# AST1080 register map
File version: 1.0
CPU: CM4 r0p1, little endian, MPU, FPU, 4 interrupt priority bits, 256 interrupts
Registers are 32-bit, read-write, reset 0x0 unless marked. A register's access mark holds for its fields unless they carry their own. Offsets are from the block's base; [hi:lo] are bit positions; {n}, {i} and the like mark numbered series; 'fields as' and 'values as' point back to an identical list.

## gpio (part 2 of 2)
Base 0x74C0B000
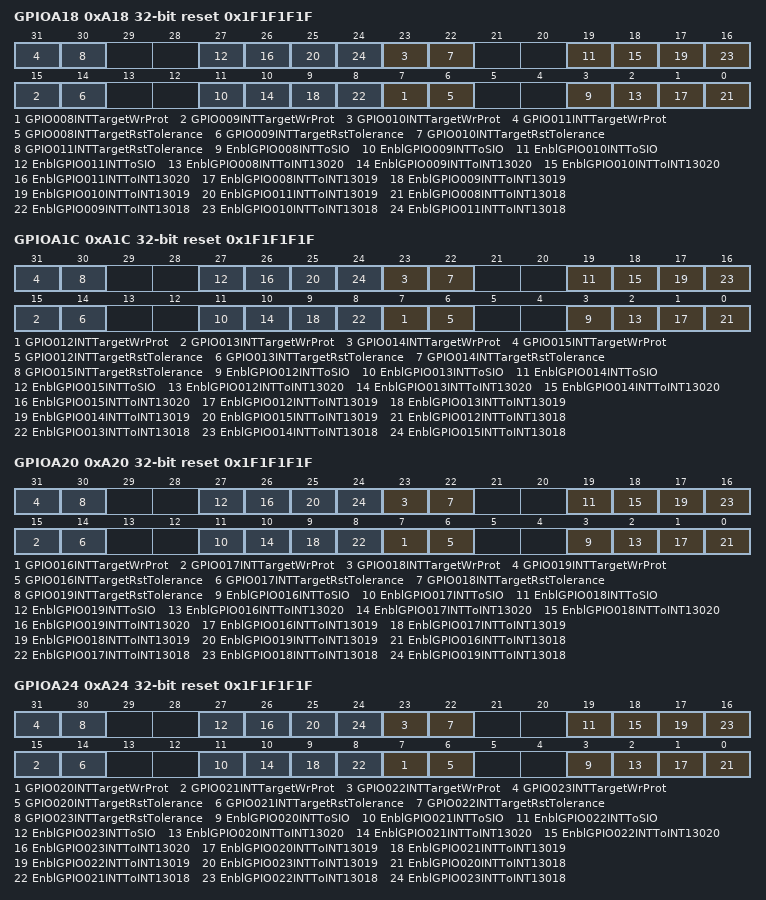
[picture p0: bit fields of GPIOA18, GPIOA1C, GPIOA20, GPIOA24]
0xA18 GPIOA18 reset 0x1F1F1F1F — GPIO Interrupt Target Control Register \#2
  [8n-57] GPIO{n:03}INTTargetWrProt (n=8..11) — GPIO{n:03} Interrupt Target Write Protection
  [8n-58] GPIO{n:03}INTTargetRstTolerance (n=8..11) — GPIO{n:03} Interrupt Target Reset Tolerance
    0=Interrupt_Target_Is_Reset_By_WDT; 1=Interrupt_Target_Is_NOT_Reset_By_WDT
  [8n-61] EnblGPIO{n:03}INTToSIO (n=8..11) — Enable GPIO{n:03} Interrupt To SIO
  [8n-62] EnblGPIO{n:03}INTToINT13020 (n=8..11) — Enable GPIO{n:03} Interrupt To INT#130_20
  [8n-63] EnblGPIO{n:03}INTToINT13019 (n=8..11) — Enable GPIO{n:03} Interrupt To INT#130_19
  [8n-64] EnblGPIO{n:03}INTToINT13018 (n=8..11) — Enable GPIO{n:03} Interrupt To INT#130_18
0xA1C GPIOA1C reset 0x1F1F1F1F — GPIO Interrupt Target Control Register \#3
  [8n-89] GPIO{n:03}INTTargetWrProt (n=12..15) — GPIO{n:03} Interrupt Target Write Protection
  [8n-90] GPIO{n:03}INTTargetRstTolerance (n=12..15) — GPIO{n:03} Interrupt Target Reset Tolerance
    values as GPIOA18.GPIO008INTTargetRstTolerance
  [8n-93] EnblGPIO{n:03}INTToSIO (n=12..15) — Enable GPIO{n:03} Interrupt To SIO
  [8n-94] EnblGPIO{n:03}INTToINT13020 (n=12..15) — Enable GPIO{n:03} Interrupt To INT#130_20
  [8n-95] EnblGPIO{n:03}INTToINT13019 (n=12..15) — Enable GPIO{n:03} Interrupt To INT#130_19
  [8n-96] EnblGPIO{n:03}INTToINT13018 (n=12..15) — Enable GPIO{n:03} Interrupt To INT#130_18
0xA20 GPIOA20 reset 0x1F1F1F1F — GPIO Interrupt Target Control Register \#4
  [8n-121] GPIO{n:03}INTTargetWrProt (n=16..19) — GPIO{n:03} Interrupt Target Write Protection
  [8n-122] GPIO{n:03}INTTargetRstTolerance (n=16..19) — GPIO{n:03} Interrupt Target Reset Tolerance
    values as GPIOA18.GPIO008INTTargetRstTolerance
  [8n-125] EnblGPIO{n:03}INTToSIO (n=16..19) — Enable GPIO{n:03} Interrupt To SIO
  [8n-126] EnblGPIO{n:03}INTToINT13020 (n=16..19) — Enable GPIO{n:03} Interrupt To INT#130_20
  [8n-127] EnblGPIO{n:03}INTToINT13019 (n=16..19) — Enable GPIO{n:03} Interrupt To INT#130_19
  [8n-128] EnblGPIO{n:03}INTToINT13018 (n=16..19) — Enable GPIO{n:03} Interrupt To INT#130_18
0xA24 GPIOA24 reset 0x1F1F1F1F — GPIO Interrupt Target Control Register \#5
  [8n-153] GPIO{n:03}INTTargetWrProt (n=20..23) — GPIO{n:03} Interrupt Target Write Protection
  [8n-154] GPIO{n:03}INTTargetRstTolerance (n=20..23) — GPIO{n:03} Interrupt Target Reset Tolerance
    values as GPIOA18.GPIO008INTTargetRstTolerance
  [8n-157] EnblGPIO{n:03}INTToSIO (n=20..23) — Enable GPIO{n:03} Interrupt To SIO
  [8n-158] EnblGPIO{n:03}INTToINT13020 (n=20..23) — Enable GPIO{n:03} Interrupt To INT#130_20
  [8n-159] EnblGPIO{n:03}INTToINT13019 (n=20..23) — Enable GPIO{n:03} Interrupt To INT#130_19
  [8n-160] EnblGPIO{n:03}INTToINT13018 (n=20..23) — Enable GPIO{n:03} Interrupt To INT#130_18
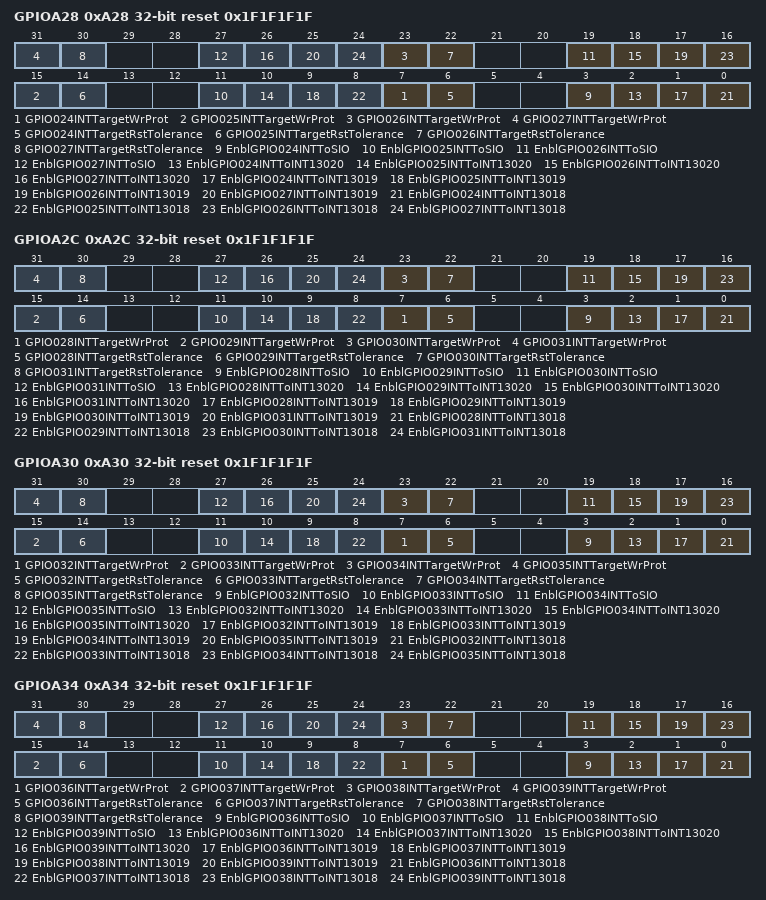
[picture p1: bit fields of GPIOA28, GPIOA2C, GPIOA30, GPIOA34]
0xA28 GPIOA28 reset 0x1F1F1F1F — GPIO Interrupt Target Control Register \#6
  [8n-185] GPIO{n:03}INTTargetWrProt (n=24..27) — GPIO{n:03} Interrupt Target Write Protection
  [8n-186] GPIO{n:03}INTTargetRstTolerance (n=24..27) — GPIO{n:03} Interrupt Target Reset Tolerance
    values as GPIOA18.GPIO008INTTargetRstTolerance
  [8n-189] EnblGPIO{n:03}INTToSIO (n=24..27) — Enable GPIO{n:03} Interrupt To SIO
  [8n-190] EnblGPIO{n:03}INTToINT13020 (n=24..27) — Enable GPIO{n:03} Interrupt To INT#130_20
  [8n-191] EnblGPIO{n:03}INTToINT13019 (n=24..27) — Enable GPIO{n:03} Interrupt To INT#130_19
  [8n-192] EnblGPIO{n:03}INTToINT13018 (n=24..27) — Enable GPIO{n:03} Interrupt To INT#130_18
0xA2C GPIOA2C reset 0x1F1F1F1F — GPIO Interrupt Target Control Register \#7
  [8n-217] GPIO{n:03}INTTargetWrProt (n=28..31) — GPIO{n:03} Interrupt Target Write Protection
  [8n-218] GPIO{n:03}INTTargetRstTolerance (n=28..31) — GPIO{n:03} Interrupt Target Reset Tolerance
    values as GPIOA18.GPIO008INTTargetRstTolerance
  [8n-221] EnblGPIO{n:03}INTToSIO (n=28..31) — Enable GPIO{n:03} Interrupt To SIO
  [8n-222] EnblGPIO{n:03}INTToINT13020 (n=28..31) — Enable GPIO{n:03} Interrupt To INT#130_20
  [8n-223] EnblGPIO{n:03}INTToINT13019 (n=28..31) — Enable GPIO{n:03} Interrupt To INT#130_19
  [8n-224] EnblGPIO{n:03}INTToINT13018 (n=28..31) — Enable GPIO{n:03} Interrupt To INT#130_18
0xA30 GPIOA30 reset 0x1F1F1F1F — GPIO Interrupt Target Control Register \#8
  [8n-249] GPIO{n:03}INTTargetWrProt (n=32..35) — GPIO{n:03} Interrupt Target Write Protection
  [8n-250] GPIO{n:03}INTTargetRstTolerance (n=32..35) — GPIO{n:03} Interrupt Target Reset Tolerance
    values as GPIOA18.GPIO008INTTargetRstTolerance
  [8n-253] EnblGPIO{n:03}INTToSIO (n=32..35) — Enable GPIO{n:03} Interrupt To SIO
  [8n-254] EnblGPIO{n:03}INTToINT13020 (n=32..35) — Enable GPIO{n:03} Interrupt To INT#130_20
  [8n-255] EnblGPIO{n:03}INTToINT13019 (n=32..35) — Enable GPIO{n:03} Interrupt To INT#130_19
  [8n-256] EnblGPIO{n:03}INTToINT13018 (n=32..35) — Enable GPIO{n:03} Interrupt To INT#130_18
0xA34 GPIOA34 reset 0x1F1F1F1F — GPIO Interrupt Target Control Register \#9
  [8n-281] GPIO{n:03}INTTargetWrProt (n=36..39) — GPIO{n:03} Interrupt Target Write Protection
  [8n-282] GPIO{n:03}INTTargetRstTolerance (n=36..39) — GPIO{n:03} Interrupt Target Reset Tolerance
    values as GPIOA18.GPIO008INTTargetRstTolerance
  [8n-285] EnblGPIO{n:03}INTToSIO (n=36..39) — Enable GPIO{n:03} Interrupt To SIO
  [8n-286] EnblGPIO{n:03}INTToINT13020 (n=36..39) — Enable GPIO{n:03} Interrupt To INT#130_20
  [8n-287] EnblGPIO{n:03}INTToINT13019 (n=36..39) — Enable GPIO{n:03} Interrupt To INT#130_19
  [8n-288] EnblGPIO{n:03}INTToINT13018 (n=36..39) — Enable GPIO{n:03} Interrupt To INT#130_18
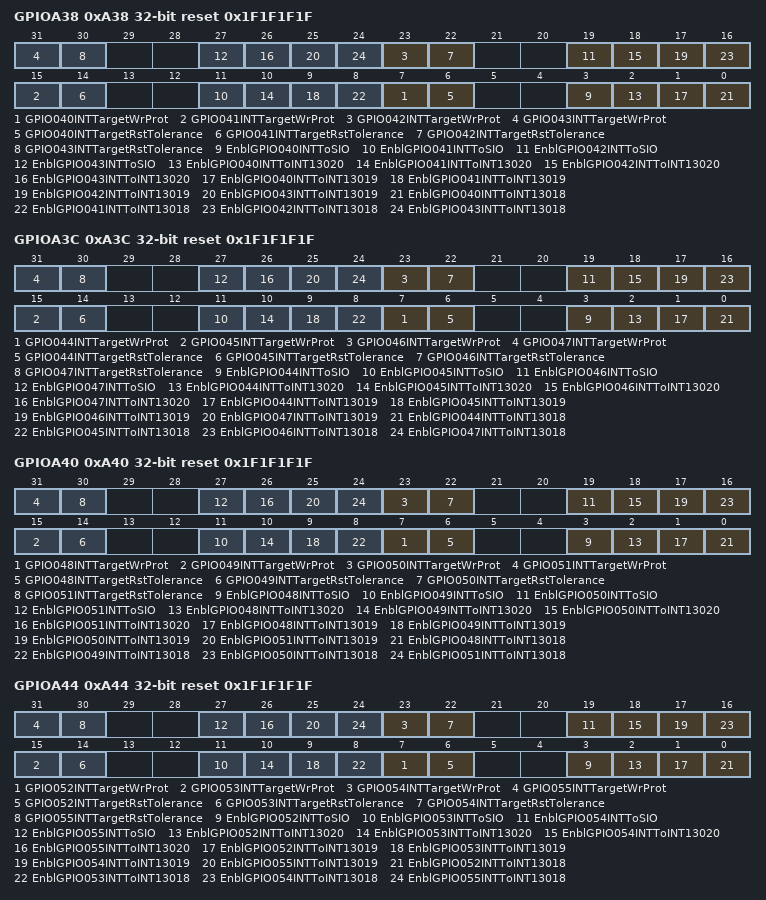
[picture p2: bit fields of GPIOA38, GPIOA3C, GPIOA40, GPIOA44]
0xA38 GPIOA38 reset 0x1F1F1F1F — GPIO Interrupt Target Control Register \#10
  [8n-313] GPIO{n:03}INTTargetWrProt (n=40..43) — GPIO{n:03} Interrupt Target Write Protection
  [8n-314] GPIO{n:03}INTTargetRstTolerance (n=40..43) — GPIO{n:03} Interrupt Target Reset Tolerance
    values as GPIOA18.GPIO008INTTargetRstTolerance
  [8n-317] EnblGPIO{n:03}INTToSIO (n=40..43) — Enable GPIO{n:03} Interrupt To SIO
  [8n-318] EnblGPIO{n:03}INTToINT13020 (n=40..43) — Enable GPIO{n:03} Interrupt To INT#130_20
  [8n-319] EnblGPIO{n:03}INTToINT13019 (n=40..43) — Enable GPIO{n:03} Interrupt To INT#130_19
  [8n-320] EnblGPIO{n:03}INTToINT13018 (n=40..43) — Enable GPIO{n:03} Interrupt To INT#130_18
0xA3C GPIOA3C reset 0x1F1F1F1F — GPIO Interrupt Target Control Register \#11
  [8n-345] GPIO{n:03}INTTargetWrProt (n=44..47) — GPIO{n:03} Interrupt Target Write Protection
  [8n-346] GPIO{n:03}INTTargetRstTolerance (n=44..47) — GPIO{n:03} Interrupt Target Reset Tolerance
    values as GPIOA18.GPIO008INTTargetRstTolerance
  [8n-349] EnblGPIO{n:03}INTToSIO (n=44..47) — Enable GPIO{n:03} Interrupt To SIO
  [8n-350] EnblGPIO{n:03}INTToINT13020 (n=44..47) — Enable GPIO{n:03} Interrupt To INT#130_20
  [8n-351] EnblGPIO{n:03}INTToINT13019 (n=44..47) — Enable GPIO{n:03} Interrupt To INT#130_19
  [8n-352] EnblGPIO{n:03}INTToINT13018 (n=44..47) — Enable GPIO{n:03} Interrupt To INT#130_18
0xA40 GPIOA40 reset 0x1F1F1F1F — GPIO Interrupt Target Control Register \#12
  [8n-377] GPIO{n:03}INTTargetWrProt (n=48..51) — GPIO{n:03} Interrupt Target Write Protection
  [8n-378] GPIO{n:03}INTTargetRstTolerance (n=48..51) — GPIO{n:03} Interrupt Target Reset Tolerance
    values as GPIOA18.GPIO008INTTargetRstTolerance
  [8n-381] EnblGPIO{n:03}INTToSIO (n=48..51) — Enable GPIO{n:03} Interrupt To SIO
  [8n-382] EnblGPIO{n:03}INTToINT13020 (n=48..51) — Enable GPIO{n:03} Interrupt To INT#130_20
  [8n-383] EnblGPIO{n:03}INTToINT13019 (n=48..51) — Enable GPIO{n:03} Interrupt To INT#130_19
  [8n-384] EnblGPIO{n:03}INTToINT13018 (n=48..51) — Enable GPIO{n:03} Interrupt To INT#130_18
0xA44 GPIOA44 reset 0x1F1F1F1F — GPIO Interrupt Target Control Register \#13
  [8n-409] GPIO{n:03}INTTargetWrProt (n=52..55) — GPIO{n:03} Interrupt Target Write Protection
  [8n-410] GPIO{n:03}INTTargetRstTolerance (n=52..55) — GPIO{n:03} Interrupt Target Reset Tolerance
    values as GPIOA18.GPIO008INTTargetRstTolerance
  [8n-413] EnblGPIO{n:03}INTToSIO (n=52..55) — Enable GPIO{n:03} Interrupt To SIO
  [8n-414] EnblGPIO{n:03}INTToINT13020 (n=52..55) — Enable GPIO{n:03} Interrupt To INT#130_20
  [8n-415] EnblGPIO{n:03}INTToINT13019 (n=52..55) — Enable GPIO{n:03} Interrupt To INT#130_19
  [8n-416] EnblGPIO{n:03}INTToINT13018 (n=52..55) — Enable GPIO{n:03} Interrupt To INT#130_18
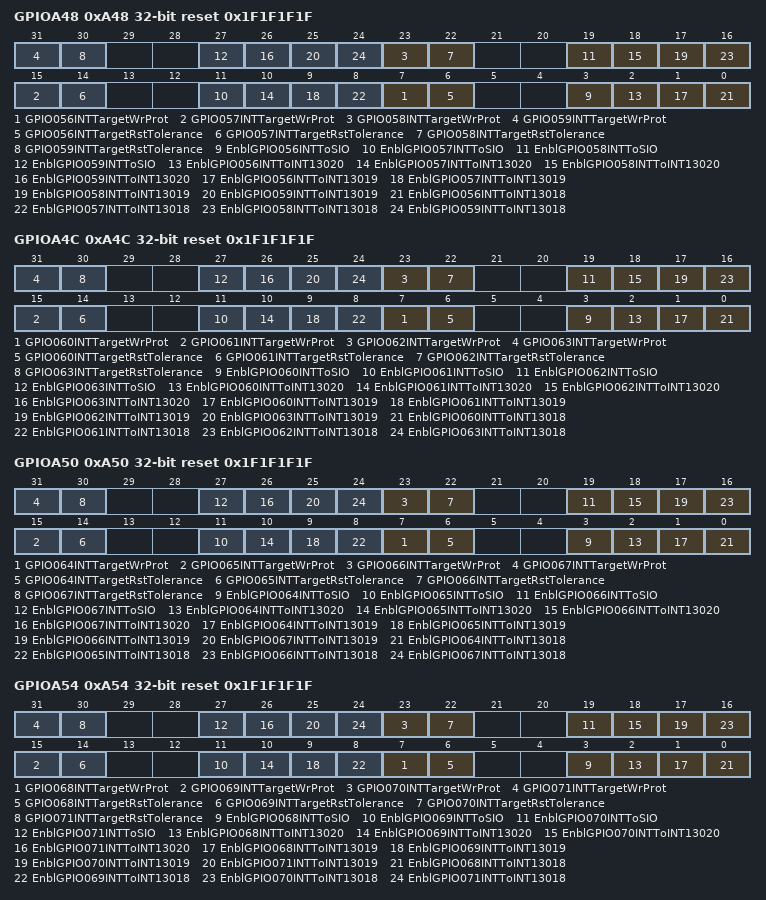
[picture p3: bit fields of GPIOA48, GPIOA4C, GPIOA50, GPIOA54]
0xA48 GPIOA48 reset 0x1F1F1F1F — GPIO Interrupt Target Control Register \#14
  [8n-441] GPIO{n:03}INTTargetWrProt (n=56..59) — GPIO{n:03} Interrupt Target Write Protection
  [8n-442] GPIO{n:03}INTTargetRstTolerance (n=56..59) — GPIO{n:03} Interrupt Target Reset Tolerance
    values as GPIOA18.GPIO008INTTargetRstTolerance
  [8n-445] EnblGPIO{n:03}INTToSIO (n=56..59) — Enable GPIO{n:03} Interrupt To SIO
  [8n-446] EnblGPIO{n:03}INTToINT13020 (n=56..59) — Enable GPIO{n:03} Interrupt To INT#130_20
  [8n-447] EnblGPIO{n:03}INTToINT13019 (n=56..59) — Enable GPIO{n:03} Interrupt To INT#130_19
  [8n-448] EnblGPIO{n:03}INTToINT13018 (n=56..59) — Enable GPIO{n:03} Interrupt To INT#130_18
0xA4C GPIOA4C reset 0x1F1F1F1F — GPIO Interrupt Target Control Register \#15
  [8n-473] GPIO{n:03}INTTargetWrProt (n=60..63) — GPIO{n:03} Interrupt Target Write Protection
  [8n-474] GPIO{n:03}INTTargetRstTolerance (n=60..63) — GPIO{n:03} Interrupt Target Reset Tolerance
    values as GPIOA18.GPIO008INTTargetRstTolerance
  [8n-477] EnblGPIO{n:03}INTToSIO (n=60..63) — Enable GPIO{n:03} Interrupt To SIO
  [8n-478] EnblGPIO{n:03}INTToINT13020 (n=60..63) — Enable GPIO{n:03} Interrupt To INT#130_20
  [8n-479] EnblGPIO{n:03}INTToINT13019 (n=60..63) — Enable GPIO{n:03} Interrupt To INT#130_19
  [8n-480] EnblGPIO{n:03}INTToINT13018 (n=60..63) — Enable GPIO{n:03} Interrupt To INT#130_18
0xA50 GPIOA50 reset 0x1F1F1F1F — GPIO Interrupt Target Control Register \#16
  [8n-505] GPIO{n:03}INTTargetWrProt (n=64..67) — GPIO{n:03} Interrupt Target Write Protection
  [8n-506] GPIO{n:03}INTTargetRstTolerance (n=64..67) — GPIO{n:03} Interrupt Target Reset Tolerance
    values as GPIOA18.GPIO008INTTargetRstTolerance
  [8n-509] EnblGPIO{n:03}INTToSIO (n=64..67) — Enable GPIO{n:03} Interrupt To SIO
  [8n-510] EnblGPIO{n:03}INTToINT13020 (n=64..67) — Enable GPIO{n:03} Interrupt To INT#130_20
  [8n-511] EnblGPIO{n:03}INTToINT13019 (n=64..67) — Enable GPIO{n:03} Interrupt To INT#130_19
  [8n-512] EnblGPIO{n:03}INTToINT13018 (n=64..67) — Enable GPIO{n:03} Interrupt To INT#130_18
0xA54 GPIOA54 reset 0x1F1F1F1F — GPIO Interrupt Target Control Register \#17
  [8n-537] GPIO{n:03}INTTargetWrProt (n=68..71) — GPIO{n:03} Interrupt Target Write Protection
  [8n-538] GPIO{n:03}INTTargetRstTolerance (n=68..71) — GPIO{n:03} Interrupt Target Reset Tolerance
    values as GPIOA18.GPIO008INTTargetRstTolerance
  [8n-541] EnblGPIO{n:03}INTToSIO (n=68..71) — Enable GPIO{n:03} Interrupt To SIO
  [8n-542] EnblGPIO{n:03}INTToINT13020 (n=68..71) — Enable GPIO{n:03} Interrupt To INT#130_20
  [8n-543] EnblGPIO{n:03}INTToINT13019 (n=68..71) — Enable GPIO{n:03} Interrupt To INT#130_19
  [8n-544] EnblGPIO{n:03}INTToINT13018 (n=68..71) — Enable GPIO{n:03} Interrupt To INT#130_18
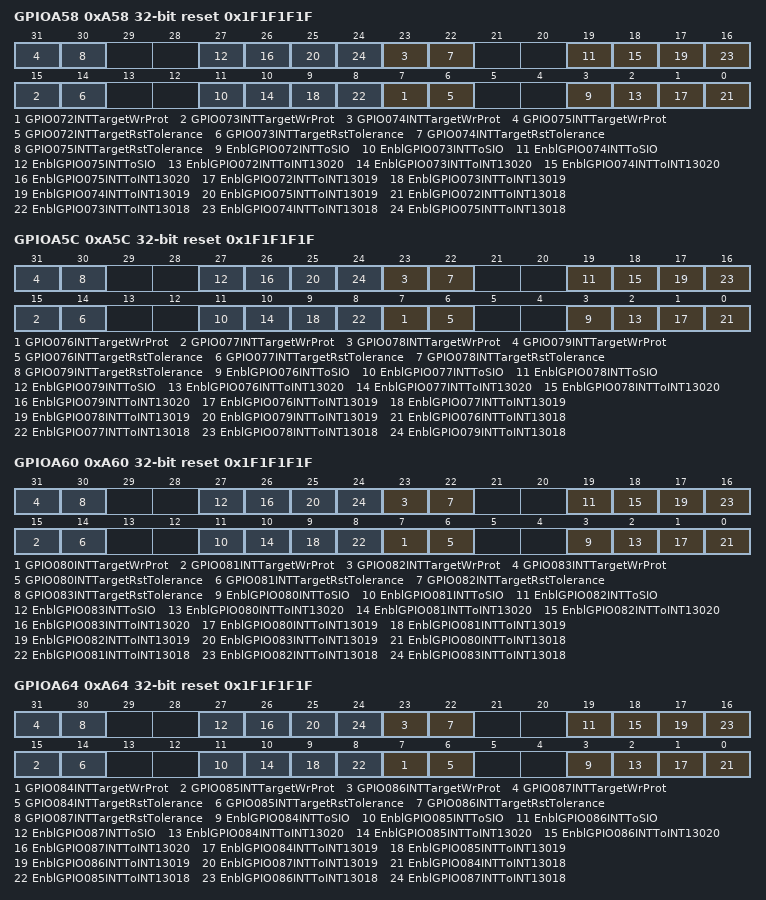
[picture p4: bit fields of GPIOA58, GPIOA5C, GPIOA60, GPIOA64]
0xA58 GPIOA58 reset 0x1F1F1F1F — GPIO Interrupt Target Control Register \#18
  [8n-569] GPIO{n:03}INTTargetWrProt (n=72..75) — GPIO{n:03} Interrupt Target Write Protection
  [8n-570] GPIO{n:03}INTTargetRstTolerance (n=72..75) — GPIO{n:03} Interrupt Target Reset Tolerance
    values as GPIOA18.GPIO008INTTargetRstTolerance
  [8n-573] EnblGPIO{n:03}INTToSIO (n=72..75) — Enable GPIO{n:03} Interrupt To SIO
  [8n-574] EnblGPIO{n:03}INTToINT13020 (n=72..75) — Enable GPIO{n:03} Interrupt To INT#130_20
  [8n-575] EnblGPIO{n:03}INTToINT13019 (n=72..75) — Enable GPIO{n:03} Interrupt To INT#130_19
  [8n-576] EnblGPIO{n:03}INTToINT13018 (n=72..75) — Enable GPIO{n:03} Interrupt To INT#130_18
0xA5C GPIOA5C reset 0x1F1F1F1F — GPIO Interrupt Target Control Register \#19
  [8n-601] GPIO{n:03}INTTargetWrProt (n=76..79) — GPIO{n:03} Interrupt Target Write Protection
  [8n-602] GPIO{n:03}INTTargetRstTolerance (n=76..79) — GPIO{n:03} Interrupt Target Reset Tolerance
    values as GPIOA18.GPIO008INTTargetRstTolerance
  [8n-605] EnblGPIO{n:03}INTToSIO (n=76..79) — Enable GPIO{n:03} Interrupt To SIO
  [8n-606] EnblGPIO{n:03}INTToINT13020 (n=76..79) — Enable GPIO{n:03} Interrupt To INT#130_20
  [8n-607] EnblGPIO{n:03}INTToINT13019 (n=76..79) — Enable GPIO{n:03} Interrupt To INT#130_19
  [8n-608] EnblGPIO{n:03}INTToINT13018 (n=76..79) — Enable GPIO{n:03} Interrupt To INT#130_18
0xA60 GPIOA60 reset 0x1F1F1F1F — GPIO Interrupt Target Control Register \#20
  [8n-633] GPIO{n:03}INTTargetWrProt (n=80..83) — GPIO{n:03} Interrupt Target Write Protection
  [8n-634] GPIO{n:03}INTTargetRstTolerance (n=80..83) — GPIO{n:03} Interrupt Target Reset Tolerance
    values as GPIOA18.GPIO008INTTargetRstTolerance
  [8n-637] EnblGPIO{n:03}INTToSIO (n=80..83) — Enable GPIO{n:03} Interrupt To SIO
  [8n-638] EnblGPIO{n:03}INTToINT13020 (n=80..83) — Enable GPIO{n:03} Interrupt To INT#130_20
  [8n-639] EnblGPIO{n:03}INTToINT13019 (n=80..83) — Enable GPIO{n:03} Interrupt To INT#130_19
  [8n-640] EnblGPIO{n:03}INTToINT13018 (n=80..83) — Enable GPIO{n:03} Interrupt To INT#130_18
0xA64 GPIOA64 reset 0x1F1F1F1F — GPIO Interrupt Target Control Register \#21
  [8n-665] GPIO{n:03}INTTargetWrProt (n=84..87) — GPIO{n:03} Interrupt Target Write Protection
  [8n-666] GPIO{n:03}INTTargetRstTolerance (n=84..87) — GPIO{n:03} Interrupt Target Reset Tolerance
    values as GPIOA18.GPIO008INTTargetRstTolerance
  [8n-669] EnblGPIO{n:03}INTToSIO (n=84..87) — Enable GPIO{n:03} Interrupt To SIO
  [8n-670] EnblGPIO{n:03}INTToINT13020 (n=84..87) — Enable GPIO{n:03} Interrupt To INT#130_20
  [8n-671] EnblGPIO{n:03}INTToINT13019 (n=84..87) — Enable GPIO{n:03} Interrupt To INT#130_19
  [8n-672] EnblGPIO{n:03}INTToINT13018 (n=84..87) — Enable GPIO{n:03} Interrupt To INT#130_18
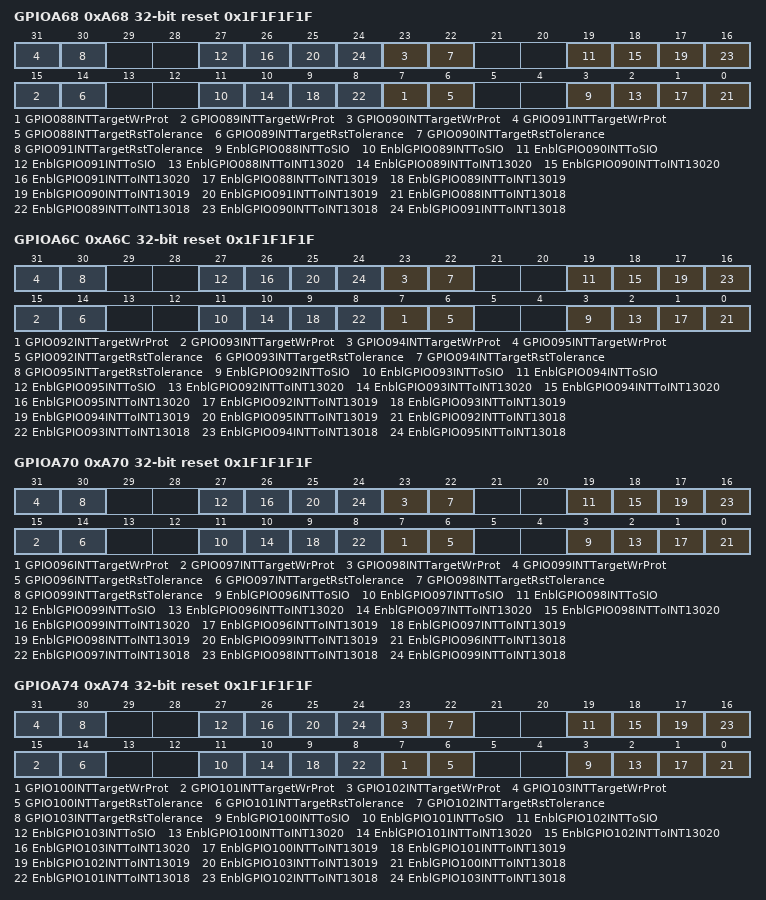
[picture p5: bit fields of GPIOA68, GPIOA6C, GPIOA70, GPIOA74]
0xA68 GPIOA68 reset 0x1F1F1F1F — GPIO Interrupt Target Control Register \#22
  [8n-697] GPIO{n:03}INTTargetWrProt (n=88..91) — GPIO{n:03} Interrupt Target Write Protection
  [8n-698] GPIO{n:03}INTTargetRstTolerance (n=88..91) — GPIO{n:03} Interrupt Target Reset Tolerance
    values as GPIOA18.GPIO008INTTargetRstTolerance
  [8n-701] EnblGPIO{n:03}INTToSIO (n=88..91) — Enable GPIO{n:03} Interrupt To SIO
  [8n-702] EnblGPIO{n:03}INTToINT13020 (n=88..91) — Enable GPIO{n:03} Interrupt To INT#130_20
  [8n-703] EnblGPIO{n:03}INTToINT13019 (n=88..91) — Enable GPIO{n:03} Interrupt To INT#130_19
  [8n-704] EnblGPIO{n:03}INTToINT13018 (n=88..91) — Enable GPIO{n:03} Interrupt To INT#130_18
0xA6C GPIOA6C reset 0x1F1F1F1F — GPIO Interrupt Target Control Register \#23
  [8n-729] GPIO{n:03}INTTargetWrProt (n=92..95) — GPIO{n:03} Interrupt Target Write Protection
  [8n-730] GPIO{n:03}INTTargetRstTolerance (n=92..95) — GPIO{n:03} Interrupt Target Reset Tolerance
    values as GPIOA18.GPIO008INTTargetRstTolerance
  [8n-733] EnblGPIO{n:03}INTToSIO (n=92..95) — Enable GPIO{n:03} Interrupt To SIO
  [8n-734] EnblGPIO{n:03}INTToINT13020 (n=92..95) — Enable GPIO{n:03} Interrupt To INT#130_20
  [8n-735] EnblGPIO{n:03}INTToINT13019 (n=92..95) — Enable GPIO{n:03} Interrupt To INT#130_19
  [8n-736] EnblGPIO{n:03}INTToINT13018 (n=92..95) — Enable GPIO{n:03} Interrupt To INT#130_18
0xA70 GPIOA70 reset 0x1F1F1F1F — GPIO Interrupt Target Control Register \#24
  [8n-761] GPIO{n:03}INTTargetWrProt (n=96..99) — GPIO{n:03} Interrupt Target Write Protection
  [8n-762] GPIO{n:03}INTTargetRstTolerance (n=96..99) — GPIO{n:03} Interrupt Target Reset Tolerance
    values as GPIOA18.GPIO008INTTargetRstTolerance
  [8n-765] EnblGPIO{n:03}INTToSIO (n=96..99) — Enable GPIO{n:03} Interrupt To SIO
  [8n-766] EnblGPIO{n:03}INTToINT13020 (n=96..99) — Enable GPIO{n:03} Interrupt To INT#130_20
  [8n-767] EnblGPIO{n:03}INTToINT13019 (n=96..99) — Enable GPIO{n:03} Interrupt To INT#130_19
  [8n-768] EnblGPIO{n:03}INTToINT13018 (n=96..99) — Enable GPIO{n:03} Interrupt To INT#130_18
0xA74 GPIOA74 reset 0x1F1F1F1F — GPIO Interrupt Target Control Register \#25
  [8n-793] GPIO{n}INTTargetWrProt (n=100..103) — GPIO{n} Interrupt Target Write Protection
  [8n-794] GPIO{n}INTTargetRstTolerance (n=100..103) — GPIO{n} Interrupt Target Reset Tolerance
    values as GPIOA18.GPIO008INTTargetRstTolerance
  [8n-797] EnblGPIO{n}INTToSIO (n=100..103) — Enable GPIO{n} Interrupt To SIO
  [8n-798] EnblGPIO{n}INTToINT13020 (n=100..103) — Enable GPIO{n} Interrupt To INT#130_20
  [8n-799] EnblGPIO{n}INTToINT13019 (n=100..103) — Enable GPIO{n} Interrupt To INT#130_19
  [8n-800] EnblGPIO{n}INTToINT13018 (n=100..103) — Enable GPIO{n} Interrupt To INT#130_18
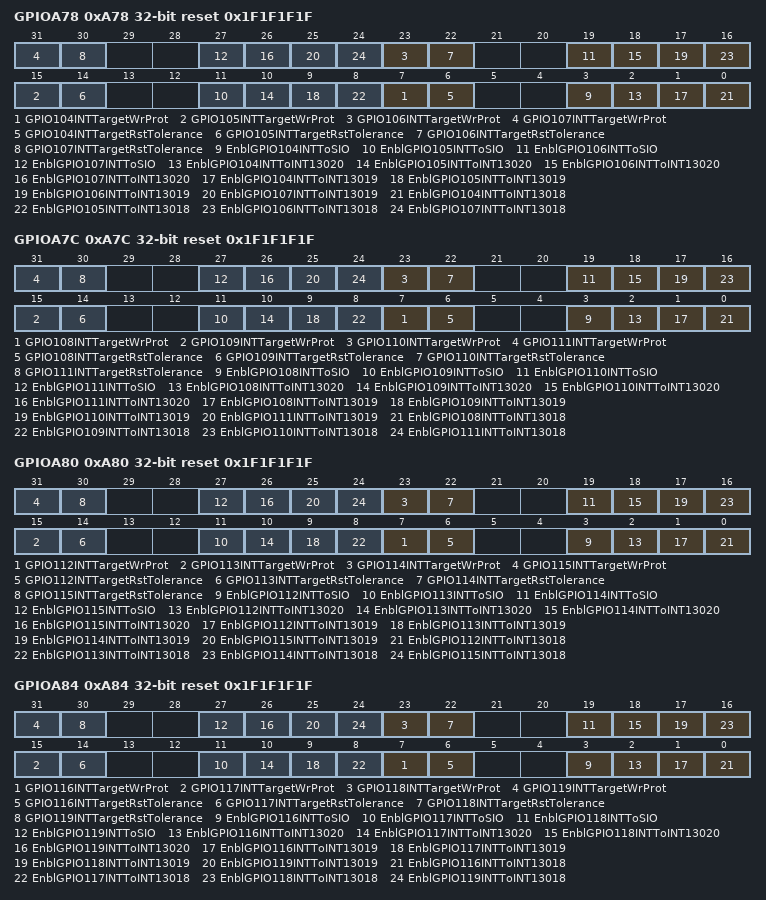
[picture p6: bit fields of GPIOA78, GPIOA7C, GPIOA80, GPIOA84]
0xA78 GPIOA78 reset 0x1F1F1F1F — GPIO Interrupt Target Control Register \#26
  [8n-825] GPIO{n}INTTargetWrProt (n=104..107) — GPIO{n} Interrupt Target Write Protection
  [8n-826] GPIO{n}INTTargetRstTolerance (n=104..107) — GPIO{n} Interrupt Target Reset Tolerance
    values as GPIOA18.GPIO008INTTargetRstTolerance
  [8n-829] EnblGPIO{n}INTToSIO (n=104..107) — Enable GPIO{n} Interrupt To SIO
  [8n-830] EnblGPIO{n}INTToINT13020 (n=104..107) — Enable GPIO{n} Interrupt To INT#130_20
  [8n-831] EnblGPIO{n}INTToINT13019 (n=104..107) — Enable GPIO{n} Interrupt To INT#130_19
  [8n-832] EnblGPIO{n}INTToINT13018 (n=104..107) — Enable GPIO{n} Interrupt To INT#130_18
0xA7C GPIOA7C reset 0x1F1F1F1F — GPIO Interrupt Target Control Register \#27
  [8n-857] GPIO{n}INTTargetWrProt (n=108..111) — GPIO{n} Interrupt Target Write Protection
  [8n-858] GPIO{n}INTTargetRstTolerance (n=108..111) — GPIO{n} Interrupt Target Reset Tolerance
    values as GPIOA18.GPIO008INTTargetRstTolerance
  [8n-861] EnblGPIO{n}INTToSIO (n=108..111) — Enable GPIO{n} Interrupt To SIO
  [8n-862] EnblGPIO{n}INTToINT13020 (n=108..111) — Enable GPIO{n} Interrupt To INT#130_20
  [8n-863] EnblGPIO{n}INTToINT13019 (n=108..111) — Enable GPIO{n} Interrupt To INT#130_19
  [8n-864] EnblGPIO{n}INTToINT13018 (n=108..111) — Enable GPIO{n} Interrupt To INT#130_18
0xA80 GPIOA80 reset 0x1F1F1F1F — GPIO Interrupt Target Control Register \#28
  [8n-889] GPIO{n}INTTargetWrProt (n=112..115) — GPIO{n} Interrupt Target Write Protection
  [8n-890] GPIO{n}INTTargetRstTolerance (n=112..115) — GPIO{n} Interrupt Target Reset Tolerance
    values as GPIOA18.GPIO008INTTargetRstTolerance
  [8n-893] EnblGPIO{n}INTToSIO (n=112..115) — Enable GPIO{n} Interrupt To SIO
  [8n-894] EnblGPIO{n}INTToINT13020 (n=112..115) — Enable GPIO{n} Interrupt To INT#130_20
  [8n-895] EnblGPIO{n}INTToINT13019 (n=112..115) — Enable GPIO{n} Interrupt To INT#130_19
  [8n-896] EnblGPIO{n}INTToINT13018 (n=112..115) — Enable GPIO{n} Interrupt To INT#130_18
0xA84 GPIOA84 reset 0x1F1F1F1F — GPIO Interrupt Target Control Register \#29
  [8n-921] GPIO{n}INTTargetWrProt (n=116..119) — GPIO{n} Interrupt Target Write Protection
  [8n-922] GPIO{n}INTTargetRstTolerance (n=116..119) — GPIO{n} Interrupt Target Reset Tolerance
    values as GPIOA18.GPIO008INTTargetRstTolerance
  [8n-925] EnblGPIO{n}INTToSIO (n=116..119) — Enable GPIO{n} Interrupt To SIO
  [8n-926] EnblGPIO{n}INTToINT13020 (n=116..119) — Enable GPIO{n} Interrupt To INT#130_20
  [8n-927] EnblGPIO{n}INTToINT13019 (n=116..119) — Enable GPIO{n} Interrupt To INT#130_19
  [8n-928] EnblGPIO{n}INTToINT13018 (n=116..119) — Enable GPIO{n} Interrupt To INT#130_18
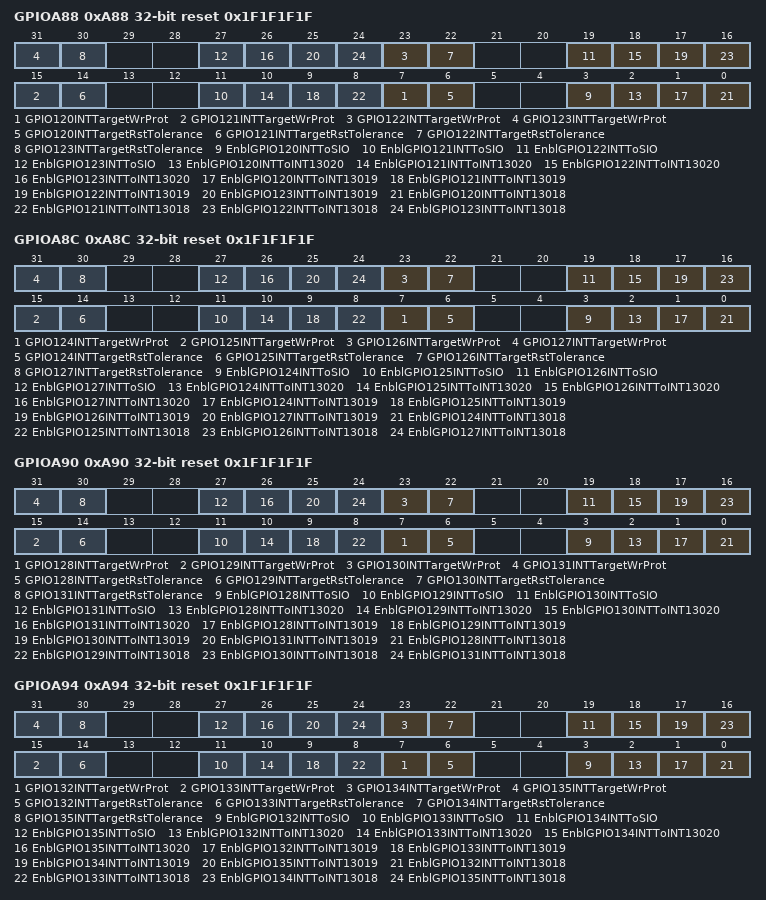
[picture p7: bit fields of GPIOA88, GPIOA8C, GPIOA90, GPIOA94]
0xA88 GPIOA88 reset 0x1F1F1F1F — GPIO Interrupt Target Control Register \#30
  [8n-953] GPIO{n}INTTargetWrProt (n=120..123) — GPIO{n} Interrupt Target Write Protection
  [8n-954] GPIO{n}INTTargetRstTolerance (n=120..123) — GPIO{n} Interrupt Target Reset Tolerance
    values as GPIOA18.GPIO008INTTargetRstTolerance
  [8n-957] EnblGPIO{n}INTToSIO (n=120..123) — Enable GPIO{n} Interrupt To SIO
  [8n-958] EnblGPIO{n}INTToINT13020 (n=120..123) — Enable GPIO{n} Interrupt To INT#130_20
  [8n-959] EnblGPIO{n}INTToINT13019 (n=120..123) — Enable GPIO{n} Interrupt To INT#130_19
  [8n-960] EnblGPIO{n}INTToINT13018 (n=120..123) — Enable GPIO{n} Interrupt To INT#130_18
0xA8C GPIOA8C reset 0x1F1F1F1F — GPIO Interrupt Target Control Register \#31
  [8n-985] GPIO{n}INTTargetWrProt (n=124..127) — GPIO{n} Interrupt Target Write Protection
  [8n-986] GPIO{n}INTTargetRstTolerance (n=124..127) — GPIO{n} Interrupt Target Reset Tolerance
    values as GPIOA18.GPIO008INTTargetRstTolerance
  [8n-989] EnblGPIO{n}INTToSIO (n=124..127) — Enable GPIO{n} Interrupt To SIO
  [8n-990] EnblGPIO{n}INTToINT13020 (n=124..127) — Enable GPIO{n} Interrupt To INT#130_20
  [8n-991] EnblGPIO{n}INTToINT13019 (n=124..127) — Enable GPIO{n} Interrupt To INT#130_19
  [8n-992] EnblGPIO{n}INTToINT13018 (n=124..127) — Enable GPIO{n} Interrupt To INT#130_18
0xA90 GPIOA90 reset 0x1F1F1F1F — GPIO Interrupt Target Control Register \#32
  [8n-1017] GPIO{n}INTTargetWrProt (n=128..131) — GPIO{n} Interrupt Target Write Protection
  [8n-1018] GPIO{n}INTTargetRstTolerance (n=128..131) — GPIO{n} Interrupt Target Reset Tolerance
    values as GPIOA18.GPIO008INTTargetRstTolerance
  [8n-1021] EnblGPIO{n}INTToSIO (n=128..131) — Enable GPIO{n} Interrupt To SIO
  [8n-1022] EnblGPIO{n}INTToINT13020 (n=128..131) — Enable GPIO{n} Interrupt To INT#130_20
  [8n-1023] EnblGPIO{n}INTToINT13019 (n=128..131) — Enable GPIO{n} Interrupt To INT#130_19
  [8n-1024] EnblGPIO{n}INTToINT13018 (n=128..131) — Enable GPIO{n} Interrupt To INT#130_18
0xA94 GPIOA94 reset 0x1F1F1F1F — GPIO Interrupt Target Control Register \#33
  [8n-1049] GPIO{n}INTTargetWrProt (n=132..135) — GPIO{n} Interrupt Target Write Protection
  [8n-1050] GPIO{n}INTTargetRstTolerance (n=132..135) — GPIO{n} Interrupt Target Reset Tolerance
    values as GPIOA18.GPIO008INTTargetRstTolerance
  [8n-1053] EnblGPIO{n}INTToSIO (n=132..135) — Enable GPIO{n} Interrupt To SIO
  [8n-1054] EnblGPIO{n}INTToINT13020 (n=132..135) — Enable GPIO{n} Interrupt To INT#130_20
  [8n-1055] EnblGPIO{n}INTToINT13019 (n=132..135) — Enable GPIO{n} Interrupt To INT#130_19
  [8n-1056] EnblGPIO{n}INTToINT13018 (n=132..135) — Enable GPIO{n} Interrupt To INT#130_18
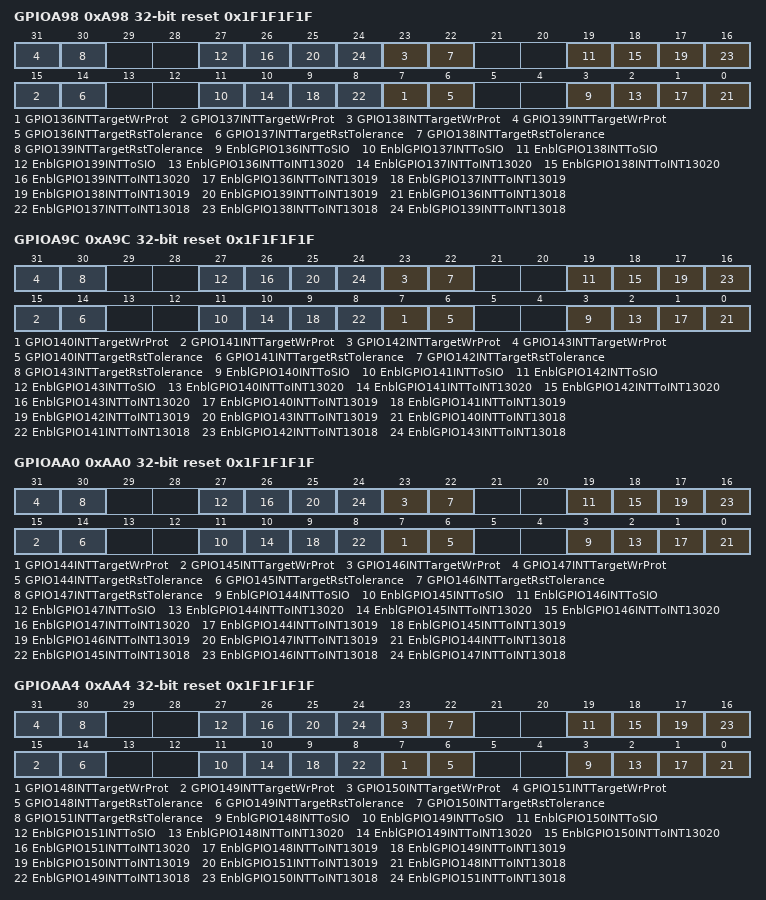
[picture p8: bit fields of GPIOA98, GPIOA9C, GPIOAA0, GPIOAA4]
0xA98 GPIOA98 reset 0x1F1F1F1F — GPIO Interrupt Target Control Register \#34
  [8n-1081] GPIO{n}INTTargetWrProt (n=136..139) — GPIO{n} Interrupt Target Write Protection
  [8n-1082] GPIO{n}INTTargetRstTolerance (n=136..139) — GPIO{n} Interrupt Target Reset Tolerance
    values as GPIOA18.GPIO008INTTargetRstTolerance
  [8n-1085] EnblGPIO{n}INTToSIO (n=136..139) — Enable GPIO{n} Interrupt To SIO
  [8n-1086] EnblGPIO{n}INTToINT13020 (n=136..139) — Enable GPIO{n} Interrupt To INT#130_20
  [8n-1087] EnblGPIO{n}INTToINT13019 (n=136..139) — Enable GPIO{n} Interrupt To INT#130_19
  [8n-1088] EnblGPIO{n}INTToINT13018 (n=136..139) — Enable GPIO{n} Interrupt To INT#130_18
0xA9C GPIOA9C reset 0x1F1F1F1F — GPIO Interrupt Target Control Register \#35
  [8n-1113] GPIO{n}INTTargetWrProt (n=140..143) — GPIO{n} Interrupt Target Write Protection
  [8n-1114] GPIO{n}INTTargetRstTolerance (n=140..143) — GPIO{n} Interrupt Target Reset Tolerance
    values as GPIOA18.GPIO008INTTargetRstTolerance
  [8n-1117] EnblGPIO{n}INTToSIO (n=140..143) — Enable GPIO{n} Interrupt To SIO
  [8n-1118] EnblGPIO{n}INTToINT13020 (n=140..143) — Enable GPIO{n} Interrupt To INT#130_20
  [8n-1119] EnblGPIO{n}INTToINT13019 (n=140..143) — Enable GPIO{n} Interrupt To INT#130_19
  [8n-1120] EnblGPIO{n}INTToINT13018 (n=140..143) — Enable GPIO{n} Interrupt To INT#130_18
0xAA0 GPIOAA0 reset 0x1F1F1F1F — GPIO Interrupt Target Control Register \#36
  [8n-1145] GPIO{n}INTTargetWrProt (n=144..147) — GPIO{n} Interrupt Target Write Protection
  [8n-1146] GPIO{n}INTTargetRstTolerance (n=144..147) — GPIO{n} Interrupt Target Reset Tolerance
    values as GPIOA18.GPIO008INTTargetRstTolerance
  [8n-1149] EnblGPIO{n}INTToSIO (n=144..147) — Enable GPIO{n} Interrupt To SIO
  [8n-1150] EnblGPIO{n}INTToINT13020 (n=144..147) — Enable GPIO{n} Interrupt To INT#130_20
  [8n-1151] EnblGPIO{n}INTToINT13019 (n=144..147) — Enable GPIO{n} Interrupt To INT#130_19
  [8n-1152] EnblGPIO{n}INTToINT13018 (n=144..147) — Enable GPIO{n} Interrupt To INT#130_18
0xAA4 GPIOAA4 reset 0x1F1F1F1F — GPIO Interrupt Target Control Register \#37
  [8n-1177] GPIO{n}INTTargetWrProt (n=148..151) — GPIO{n} Interrupt Target Write Protection
  [8n-1178] GPIO{n}INTTargetRstTolerance (n=148..151) — GPIO{n} Interrupt Target Reset Tolerance
    values as GPIOA18.GPIO008INTTargetRstTolerance
  [8n-1181] EnblGPIO{n}INTToSIO (n=148..151) — Enable GPIO{n} Interrupt To SIO
  [8n-1182] EnblGPIO{n}INTToINT13020 (n=148..151) — Enable GPIO{n} Interrupt To INT#130_20
  [8n-1183] EnblGPIO{n}INTToINT13019 (n=148..151) — Enable GPIO{n} Interrupt To INT#130_19
  [8n-1184] EnblGPIO{n}INTToINT13018 (n=148..151) — Enable GPIO{n} Interrupt To INT#130_18
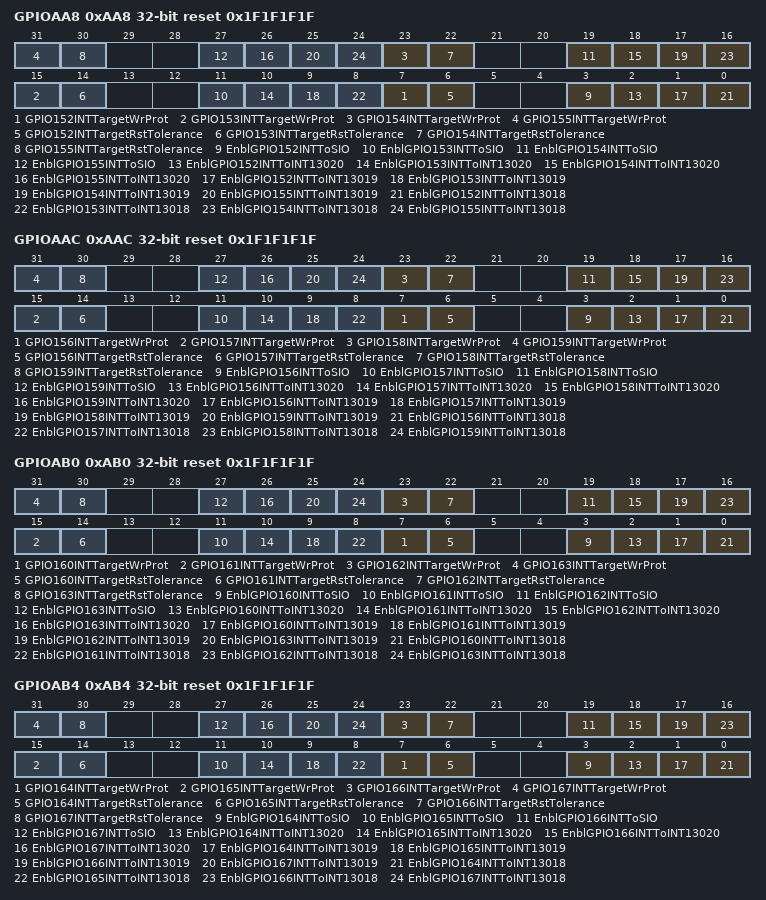
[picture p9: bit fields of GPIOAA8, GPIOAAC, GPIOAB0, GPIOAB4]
0xAA8 GPIOAA8 reset 0x1F1F1F1F — GPIO Interrupt Target Control Register \#38
  [8n-1209] GPIO{n}INTTargetWrProt (n=152..155) — GPIO{n} Interrupt Target Write Protection
  [8n-1210] GPIO{n}INTTargetRstTolerance (n=152..155) — GPIO{n} Interrupt Target Reset Tolerance
    values as GPIOA18.GPIO008INTTargetRstTolerance
  [8n-1213] EnblGPIO{n}INTToSIO (n=152..155) — Enable GPIO{n} Interrupt To SIO
  [8n-1214] EnblGPIO{n}INTToINT13020 (n=152..155) — Enable GPIO{n} Interrupt To INT#130_20
  [8n-1215] EnblGPIO{n}INTToINT13019 (n=152..155) — Enable GPIO{n} Interrupt To INT#130_19
  [8n-1216] EnblGPIO{n}INTToINT13018 (n=152..155) — Enable GPIO{n} Interrupt To INT#130_18
0xAAC GPIOAAC reset 0x1F1F1F1F — GPIO Interrupt Target Control Register \#39
  [8n-1241] GPIO{n}INTTargetWrProt (n=156..159) — GPIO{n} Interrupt Target Write Protection
  [8n-1242] GPIO{n}INTTargetRstTolerance (n=156..159) — GPIO{n} Interrupt Target Reset Tolerance
    values as GPIOA18.GPIO008INTTargetRstTolerance
  [8n-1245] EnblGPIO{n}INTToSIO (n=156..159) — Enable GPIO{n} Interrupt To SIO
  [8n-1246] EnblGPIO{n}INTToINT13020 (n=156..159) — Enable GPIO{n} Interrupt To INT#130_20
  [8n-1247] EnblGPIO{n}INTToINT13019 (n=156..159) — Enable GPIO{n} Interrupt To INT#130_19
  [8n-1248] EnblGPIO{n}INTToINT13018 (n=156..159) — Enable GPIO{n} Interrupt To INT#130_18
0xAB0 GPIOAB0 reset 0x1F1F1F1F — GPIO Interrupt Target Control Register \#40
  [8n-1273] GPIO{n}INTTargetWrProt (n=160..163) — GPIO{n} Interrupt Target Write Protection
  [8n-1274] GPIO{n}INTTargetRstTolerance (n=160..163) — GPIO{n} Interrupt Target Reset Tolerance
    values as GPIOA18.GPIO008INTTargetRstTolerance
  [8n-1277] EnblGPIO{n}INTToSIO (n=160..163) — Enable GPIO{n} Interrupt To SIO
  [8n-1278] EnblGPIO{n}INTToINT13020 (n=160..163) — Enable GPIO{n} Interrupt To INT#130_20
  [8n-1279] EnblGPIO{n}INTToINT13019 (n=160..163) — Enable GPIO{n} Interrupt To INT#130_19
  [8n-1280] EnblGPIO{n}INTToINT13018 (n=160..163) — Enable GPIO{n} Interrupt To INT#130_18
0xAB4 GPIOAB4 reset 0x1F1F1F1F — GPIO Interrupt Target Control Register \#41
  [8n-1305] GPIO{n}INTTargetWrProt (n=164..167) — GPIO{n} Interrupt Target Write Protection
  [8n-1306] GPIO{n}INTTargetRstTolerance (n=164..167) — GPIO{n} Interrupt Target Reset Tolerance
    values as GPIOA18.GPIO008INTTargetRstTolerance
  [8n-1309] EnblGPIO{n}INTToSIO (n=164..167) — Enable GPIO{n} Interrupt To SIO
  [8n-1310] EnblGPIO{n}INTToINT13020 (n=164..167) — Enable GPIO{n} Interrupt To INT#130_20
  [8n-1311] EnblGPIO{n}INTToINT13019 (n=164..167) — Enable GPIO{n} Interrupt To INT#130_19
  [8n-1312] EnblGPIO{n}INTToINT13018 (n=164..167) — Enable GPIO{n} Interrupt To INT#130_18
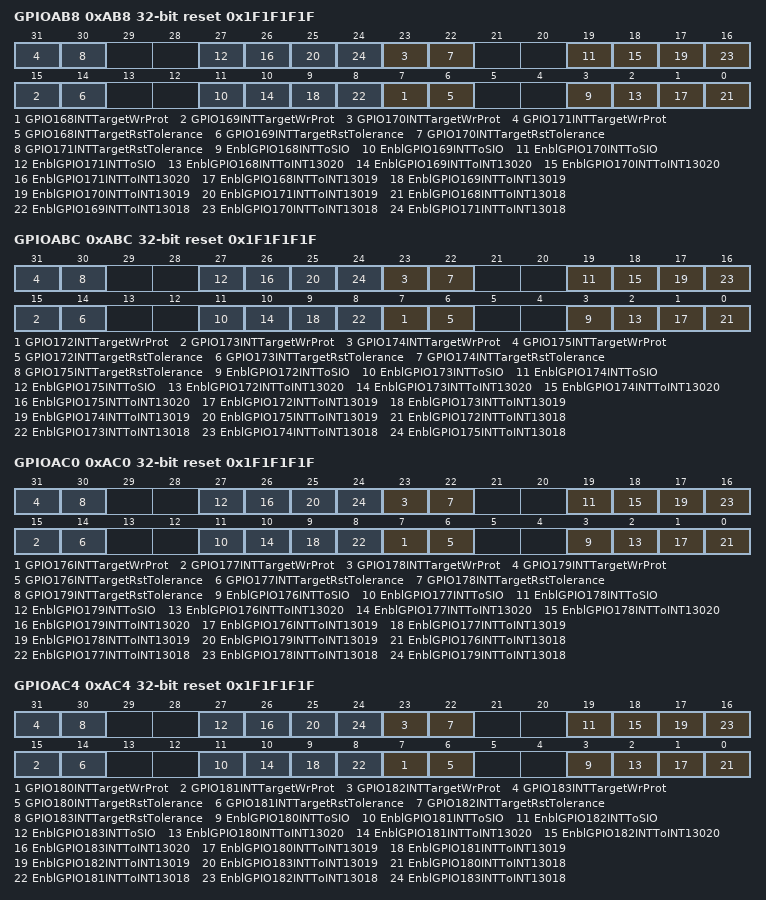
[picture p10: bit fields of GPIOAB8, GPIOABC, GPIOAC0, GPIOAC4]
0xAB8 GPIOAB8 reset 0x1F1F1F1F — GPIO Interrupt Target Control Register \#42
  [8n-1337] GPIO{n}INTTargetWrProt (n=168..171) — GPIO{n} Interrupt Target Write Protection
  [8n-1338] GPIO{n}INTTargetRstTolerance (n=168..171) — GPIO{n} Interrupt Target Reset Tolerance
    values as GPIOA18.GPIO008INTTargetRstTolerance
  [8n-1341] EnblGPIO{n}INTToSIO (n=168..171) — Enable GPIO{n} Interrupt To SIO
  [8n-1342] EnblGPIO{n}INTToINT13020 (n=168..171) — Enable GPIO{n} Interrupt To INT#130_20
  [8n-1343] EnblGPIO{n}INTToINT13019 (n=168..171) — Enable GPIO{n} Interrupt To INT#130_19
  [8n-1344] EnblGPIO{n}INTToINT13018 (n=168..171) — Enable GPIO{n} Interrupt To INT#130_18
0xABC GPIOABC reset 0x1F1F1F1F — GPIO Interrupt Target Control Register \#43
  [8n-1369] GPIO{n}INTTargetWrProt (n=172..175) — GPIO{n} Interrupt Target Write Protection
  [8n-1370] GPIO{n}INTTargetRstTolerance (n=172..175) — GPIO{n} Interrupt Target Reset Tolerance
    values as GPIOA18.GPIO008INTTargetRstTolerance
  [8n-1373] EnblGPIO{n}INTToSIO (n=172..175) — Enable GPIO{n} Interrupt To SIO
  [8n-1374] EnblGPIO{n}INTToINT13020 (n=172..175) — Enable GPIO{n} Interrupt To INT#130_20
  [8n-1375] EnblGPIO{n}INTToINT13019 (n=172..175) — Enable GPIO{n} Interrupt To INT#130_19
  [8n-1376] EnblGPIO{n}INTToINT13018 (n=172..175) — Enable GPIO{n} Interrupt To INT#130_18
0xAC0 GPIOAC0 reset 0x1F1F1F1F — GPIO Interrupt Target Control Register \#44
  [8n-1401] GPIO{n}INTTargetWrProt (n=176..179) — GPIO{n} Interrupt Target Write Protection
  [8n-1402] GPIO{n}INTTargetRstTolerance (n=176..179) — GPIO{n} Interrupt Target Reset Tolerance
    values as GPIOA18.GPIO008INTTargetRstTolerance
  [8n-1405] EnblGPIO{n}INTToSIO (n=176..179) — Enable GPIO{n} Interrupt To SIO
  [8n-1406] EnblGPIO{n}INTToINT13020 (n=176..179) — Enable GPIO{n} Interrupt To INT#130_20
  [8n-1407] EnblGPIO{n}INTToINT13019 (n=176..179) — Enable GPIO{n} Interrupt To INT#130_19
  [8n-1408] EnblGPIO{n}INTToINT13018 (n=176..179) — Enable GPIO{n} Interrupt To INT#130_18
0xAC4 GPIOAC4 reset 0x1F1F1F1F — GPIO Interrupt Target Control Register \#45
  [8n-1433] GPIO{n}INTTargetWrProt (n=180..183) — GPIO{n} Interrupt Target Write Protection
  [8n-1434] GPIO{n}INTTargetRstTolerance (n=180..183) — GPIO{n} Interrupt Target Reset Tolerance
    values as GPIOA18.GPIO008INTTargetRstTolerance
  [8n-1437] EnblGPIO{n}INTToSIO (n=180..183) — Enable GPIO{n} Interrupt To SIO
  [8n-1438] EnblGPIO{n}INTToINT13020 (n=180..183) — Enable GPIO{n} Interrupt To INT#130_20
  [8n-1439] EnblGPIO{n}INTToINT13019 (n=180..183) — Enable GPIO{n} Interrupt To INT#130_19
  [8n-1440] EnblGPIO{n}INTToINT13018 (n=180..183) — Enable GPIO{n} Interrupt To INT#130_18
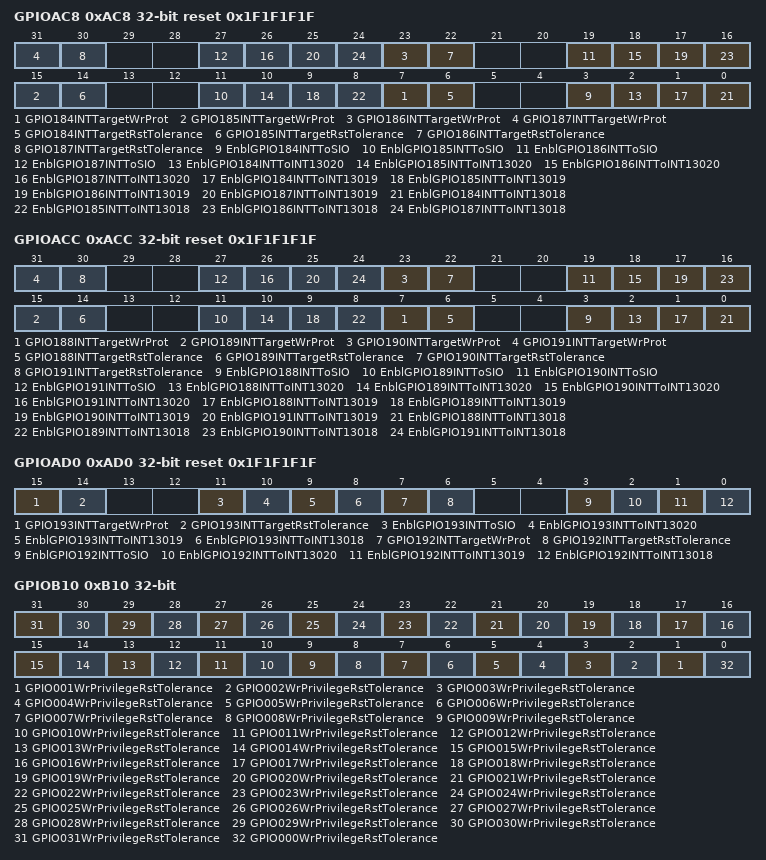
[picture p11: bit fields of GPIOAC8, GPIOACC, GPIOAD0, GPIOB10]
0xAC8 GPIOAC8 reset 0x1F1F1F1F — GPIO Interrupt Target Control Register \#46
  [8n-1465] GPIO{n}INTTargetWrProt (n=184..187) — GPIO{n} Interrupt Target Write Protection
  [8n-1466] GPIO{n}INTTargetRstTolerance (n=184..187) — GPIO{n} Interrupt Target Reset Tolerance
    values as GPIOA18.GPIO008INTTargetRstTolerance
  [8n-1469] EnblGPIO{n}INTToSIO (n=184..187) — Enable GPIO{n} Interrupt To SIO
  [8n-1470] EnblGPIO{n}INTToINT13020 (n=184..187) — Enable GPIO{n} Interrupt To INT#130_20
  [8n-1471] EnblGPIO{n}INTToINT13019 (n=184..187) — Enable GPIO{n} Interrupt To INT#130_19
  [8n-1472] EnblGPIO{n}INTToINT13018 (n=184..187) — Enable GPIO{n} Interrupt To INT#130_18
0xACC GPIOACC reset 0x1F1F1F1F — GPIO Interrupt Target Control Register \#47
  [8n-1497] GPIO{n}INTTargetWrProt (n=188..191) — GPIO{n} Interrupt Target Write Protection
  [8n-1498] GPIO{n}INTTargetRstTolerance (n=188..191) — GPIO{n} Interrupt Target Reset Tolerance
    values as GPIOA18.GPIO008INTTargetRstTolerance
  [8n-1501] EnblGPIO{n}INTToSIO (n=188..191) — Enable GPIO{n} Interrupt To SIO
  [8n-1502] EnblGPIO{n}INTToINT13020 (n=188..191) — Enable GPIO{n} Interrupt To INT#130_20
  [8n-1503] EnblGPIO{n}INTToINT13019 (n=188..191) — Enable GPIO{n} Interrupt To INT#130_19
  [8n-1504] EnblGPIO{n}INTToINT13018 (n=188..191) — Enable GPIO{n} Interrupt To INT#130_18
0xAD0 GPIOAD0 reset 0x1F1F1F1F — GPIO Interrupt Target Control Register \#48
  [15] GPIO193INTTargetWrProt — GPIO193 Interrupt Target Write Protection
  [14] GPIO193INTTargetRstTolerance — GPIO193 Interrupt Target Reset Tolerance
    values as GPIOA18.GPIO008INTTargetRstTolerance
  [11] EnblGPIO193INTToSIO — Enable GPIO193 Interrupt To SIO
  [10] EnblGPIO193INTToINT13020 — Enable GPIO193 Interrupt To INT#130_20
  [9] EnblGPIO193INTToINT13019 — Enable GPIO193 Interrupt To INT#130_19
  [8] EnblGPIO193INTToINT13018 — Enable GPIO193 Interrupt To INT#130_18
  [7] GPIO192INTTargetWrProt — GPIO192 Interrupt Target Write Protection
  [6] GPIO192INTTargetRstTolerance — GPIO192 Interrupt Target Reset Tolerance
    values as GPIOA18.GPIO008INTTargetRstTolerance
  [3] EnblGPIO192INTToSIO — Enable GPIO192 Interrupt To SIO
  [2] EnblGPIO192INTToINT13020 — Enable GPIO192 Interrupt To INT#130_20
  [1] EnblGPIO192INTToINT13019 — Enable GPIO192 Interrupt To INT#130_19
  [0] EnblGPIO192INTToINT13018 — Enable GPIO192 Interrupt To INT#130_18
0xB10 GPIOB10 — Write Privilege Reset Tolerance Register \#1
  [n] GPIO{n:03}WrPrivilegeRstTolerance (n=1..31) — GPIO{n:03} Write Privilege Reset Tolerance
  [0] GPIO000WrPrivilegeRstTolerance — GPIO000 Write Privilege Reset Tolerance
    0=Write_Privilege_Of_GPIO000_Is_Reset_By_WDT; 1=Write_Privilege_Of_GPIO000_Is_NOT_Reset_By_WDT
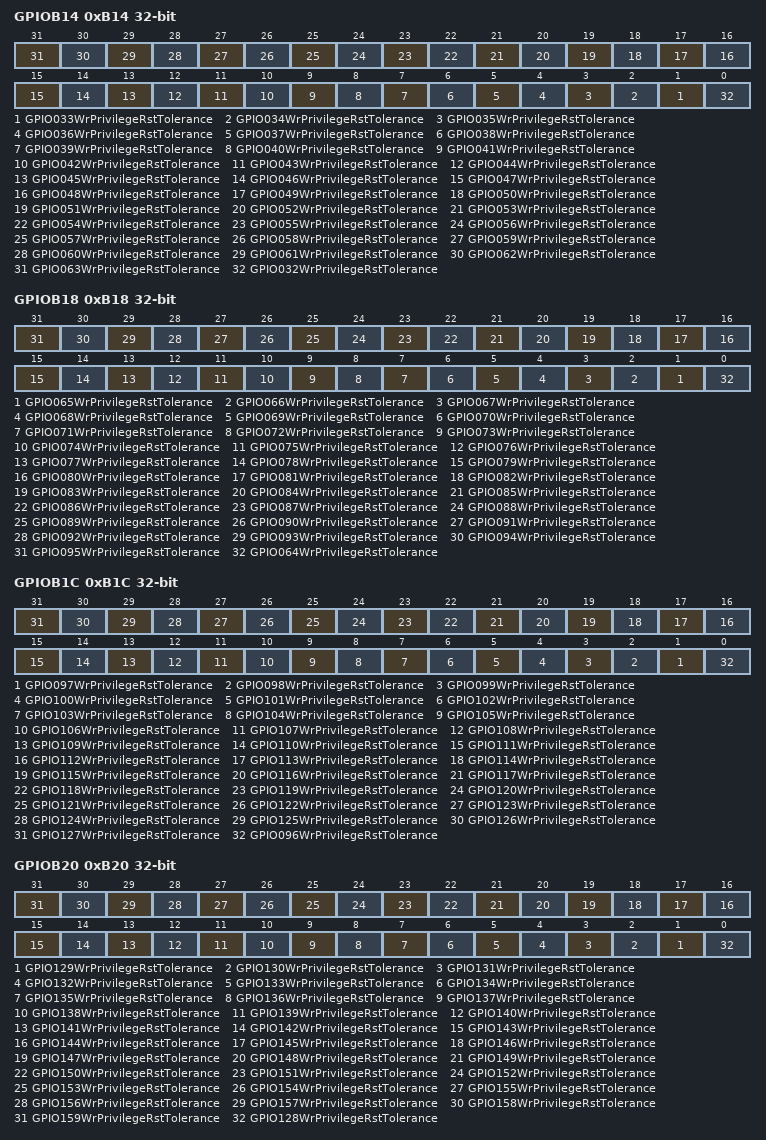
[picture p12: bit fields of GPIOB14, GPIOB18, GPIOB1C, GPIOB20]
0xB14 GPIOB14 — Write Privilege Reset Tolerance Register \#2
  [n-32] GPIO{n:03}WrPrivilegeRstTolerance (n=33..63) — GPIO{n:03} Write Privilege Reset Tolerance
  [0] GPIO032WrPrivilegeRstTolerance — GPIO032 Write Privilege Reset Tolerance
    0=Write_Privilege_Of_GPIO032_Is_Reset_By_WDT; 1=Write_Privilege_Of_GPIO032_Is_NOT_Reset_By_WDT
0xB18 GPIOB18 — Write Privilege Reset Tolerance Register \#3
  [n-64] GPIO{n:03}WrPrivilegeRstTolerance (n=65..95) — GPIO{n:03} Write Privilege Reset Tolerance
  [0] GPIO064WrPrivilegeRstTolerance — GPIO064 Write Privilege Reset Tolerance
    0=Write_Privilege_Of_GPIO064_Is_Reset_By_WDT; 1=Write_Privilege_Of_GPIO064_Is_NOT_Reset_By_WDT
0xB1C GPIOB1C — Write Privilege Reset Tolerance Register \#4
  [n-96] GPIO{n:03}WrPrivilegeRstTolerance (n=97..127) — GPIO{n:03} Write Privilege Reset Tolerance
  [0] GPIO096WrPrivilegeRstTolerance — GPIO096 Write Privilege Reset Tolerance
    0=Write_Privilege_Of_GPIO096_Is_Reset_By_WDT; 1=Write_Privilege_Of_GPIO096_Is_NOT_Reset_By_WDT
0xB20 GPIOB20 — Write Privilege Reset Tolerance Register \#5
  [n-128] GPIO{n}WrPrivilegeRstTolerance (n=129..159) — GPIO{n} Write Privilege Reset Tolerance
  [0] GPIO128WrPrivilegeRstTolerance — GPIO128 Write Privilege Reset Tolerance
    0=Write_Privilege_Of_GPIO128_Is_Reset_By_WDT; 1=Write_Privilege_Of_GPIO128_Is_NOT_Reset_By_WDT
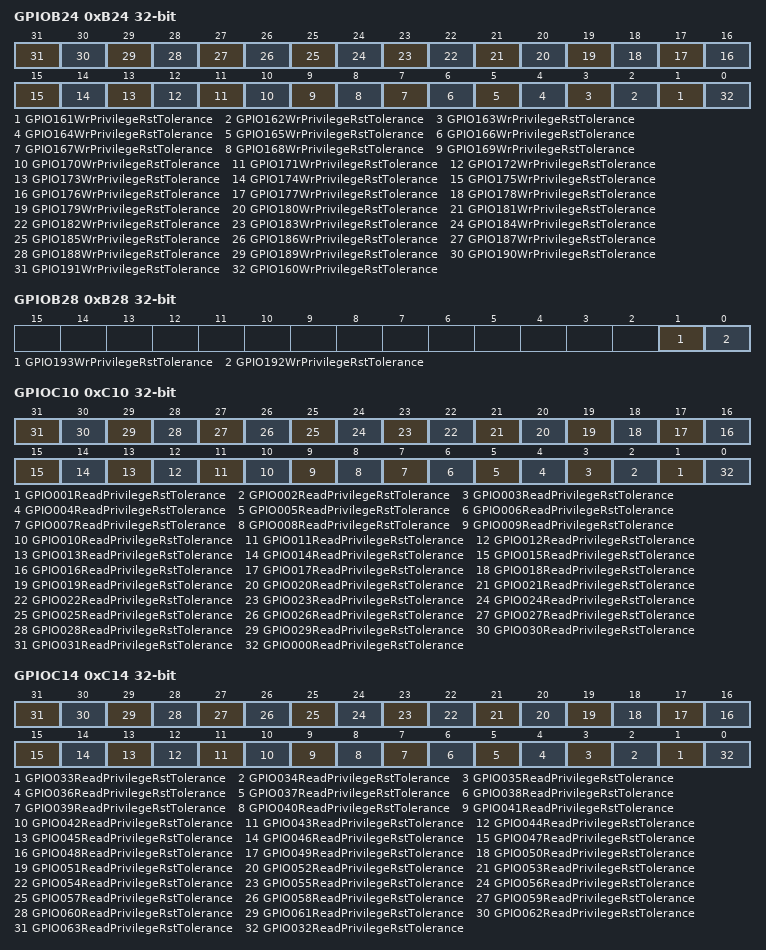
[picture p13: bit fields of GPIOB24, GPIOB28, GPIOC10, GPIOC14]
0xB24 GPIOB24 — Write Privilege Reset Tolerance Register \#6
  [n-160] GPIO{n}WrPrivilegeRstTolerance (n=161..191) — GPIO{n} Write Privilege Reset Tolerance
  [0] GPIO160WrPrivilegeRstTolerance — GPIO160 Write Privilege Reset Tolerance
    0=Write_Privilege_Of_GPIO160_Is_Reset_By_WDT; 1=Write_Privilege_Of_GPIO160_Is_NOT_Reset_By_WDT
0xB28 GPIOB28 — Write Privilege Reset Tolerance Register \#7
  [1] GPIO193WrPrivilegeRstTolerance — GPIO193 Write Privilege Reset Tolerance
  [0] GPIO192WrPrivilegeRstTolerance — GPIO192 Write Privilege Reset Tolerance
    0=Write_Privilege_Of_GPIO192_Is_Reset_By_WDT; 1=Write_Privilege_Of_GPIO192_Is_NOT_Reset_By_WDT
0xC10 GPIOC10 — Read Privilege Reset Tolerance Register \#1
  [n] GPIO{n:03}ReadPrivilegeRstTolerance (n=1..31) — GPIO{n:03} Read Privilege Reset Tolerance
  [0] GPIO000ReadPrivilegeRstTolerance — GPIO000 Read Privilege Reset Tolerance
    0=Read_Privilege_Of_GPIO000_Is_Reset_By_WDT; 1=Read_Privilege_Of_GPIO000_Is_NOT_Reset_By_WDT
0xC14 GPIOC14 — Read Privilege Reset Tolerance Register \#2
  [n-32] GPIO{n:03}ReadPrivilegeRstTolerance (n=33..63) — GPIO{n:03} Read Privilege Reset Tolerance
  [0] GPIO032ReadPrivilegeRstTolerance — GPIO032 Read Privilege Reset Tolerance
    0=Read_Privilege_Of_GPIO032_Is_Reset_By_WDT; 1=Read_Privilege_Of_GPIO032_Is_NOT_Reset_By_WDT
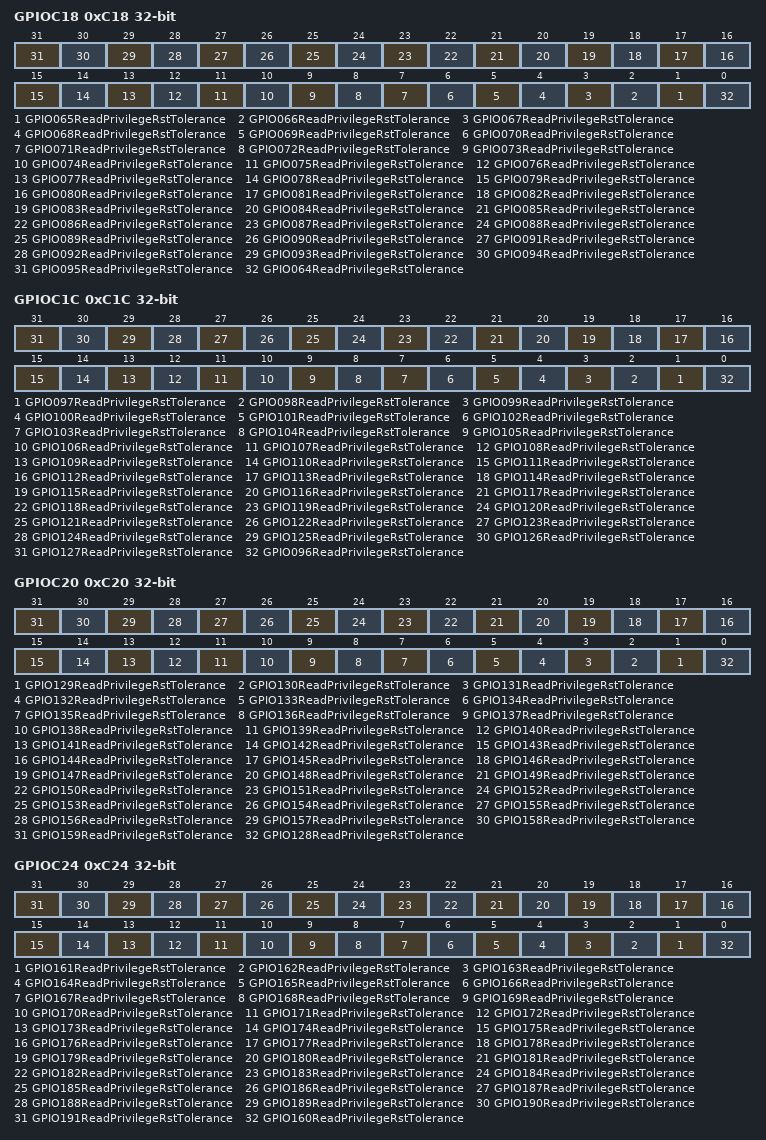
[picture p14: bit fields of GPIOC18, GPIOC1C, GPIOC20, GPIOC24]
0xC18 GPIOC18 — Read Privilege Reset Tolerance Register \#3
  [n-64] GPIO{n:03}ReadPrivilegeRstTolerance (n=65..95) — GPIO{n:03} Read Privilege Reset Tolerance
  [0] GPIO064ReadPrivilegeRstTolerance — GPIO064 Read Privilege Reset Tolerance
    0=Read_Privilege_Of_GPIO064_Is_Reset_By_WDT; 1=Read_Privilege_Of_GPIO064_Is_NOT_Reset_By_WDT
0xC1C GPIOC1C — Read Privilege Reset Tolerance Register \#4
  [n-96] GPIO{n:03}ReadPrivilegeRstTolerance (n=97..127) — GPIO{n:03} Read Privilege Reset Tolerance
  [0] GPIO096ReadPrivilegeRstTolerance — GPIO096 Read Privilege Reset Tolerance
    0=Read_Privilege_Of_GPIO096_Is_Reset_By_WDT; 1=Read_Privilege_Of_GPIO096_Is_NOT_Reset_By_WDT
0xC20 GPIOC20 — Read Privilege Reset Tolerance Register \#5
  [n-128] GPIO{n}ReadPrivilegeRstTolerance (n=129..159) — GPIO{n} Read Privilege Reset Tolerance
  [0] GPIO128ReadPrivilegeRstTolerance — GPIO128 Read Privilege Reset Tolerance
    0=Read_Privilege_Of_GPIO128_Is_Reset_By_WDT; 1=Read_Privilege_Of_GPIO128_Is_NOT_Reset_By_WDT
0xC24 GPIOC24 — Read Privilege Reset Tolerance Register \#6
  [n-160] GPIO{n}ReadPrivilegeRstTolerance (n=161..191) — GPIO{n} Read Privilege Reset Tolerance
  [0] GPIO160ReadPrivilegeRstTolerance — GPIO160 Read Privilege Reset Tolerance
    0=Read_Privilege_Of_GPIO160_Is_Reset_By_WDT; 1=Read_Privilege_Of_GPIO160_Is_NOT_Reset_By_WDT
0xC28 GPIOC28 — Read Privilege Reset Tolerance Register \#7
  [1] GPIO193ReadPrivilegeRstTolerance — GPIO193 Read Privilege Reset Tolerance
  [0] GPIO192ReadPrivilegeRstTolerance — GPIO192 Read Privilege Reset Tolerance
    0=Read_Privilege_Of_GPIO192_Is_Reset_By_WDT; 1=Read_Privilege_Of_GPIO192_Is_NOT_Reset_By_WDT
0xD10 GPIOD10 — Write Privilege Write Protection Register \#1
  [n] GPIO{n:03}WrPrivilegeWriteProt (n=0..31) — GPIO{n:03} Write Privilege Write Protection
0xD14 GPIOD14 — Write Privilege Write Protection Register \#2
  [n-32] GPIO{n:03}WrPrivilegeWriteProt (n=32..63) — GPIO{n:03} Write Privilege Write Protection
0xD18 GPIOD18 — Write Privilege Write Protection Register \#3
  [n-64] GPIO{n:03}WrPrivilegeWriteProt (n=64..95) — GPIO{n:03} Write Privilege Write Protection
0xD1C GPIOD1C — Write Privilege Write Protection Register \#4
  [n-96] GPIO{n:03}WrPrivilegeWriteProt (n=96..127) — GPIO{n:03} Write Privilege Write Protection
0xD20 GPIOD20 — Write Privilege Write Protection Register \#5
  [n-128] GPIO{n}WrPrivilegeWriteProt (n=128..159) — GPIO{n} Write Privilege Write Protection
0xD24 GPIOD24 — Write Privilege Write Protection Register \#6
  [n-160] GPIO{n}WrPrivilegeWriteProt (n=160..191) — GPIO{n} Write Privilege Write Protection
0xD28 GPIOD28 — Write Privilege Write Protection Register \#7
  [1] GPIO193WrPrivilegeWriteProt — GPIO193 Write Privilege Write Protection
  [0] GPIO192WrPrivilegeWriteProt — GPIO192 Write Privilege Write Protection
0xE10 GPIOE10 — Read Privilege Write Protection Register \#1
  [n] GPIO{n:03}ReadPrivilegeWrProt (n=0..31) — GPIO{n:03} Read Privilege Write Protection
0xE14 GPIOE14 — Read Privilege Write Protection Register \#2
  [n-32] GPIO{n:03}ReadPrivilegeWrProt (n=32..63) — GPIO{n:03} Read Privilege Write Protection
0xE18 GPIOE18 — Read Privilege Write Protection Register \#3
  [n-64] GPIO{n:03}ReadPrivilegeWrProt (n=64..95) — GPIO{n:03} Read Privilege Write Protection
0xE1C GPIOE1C — Read Privilege Write Protection Register \#4
  [n-96] GPIO{n:03}ReadPrivilegeWrProt (n=96..127) — GPIO{n:03} Read Privilege Write Protection
0xE20 GPIOE20 — Read Privilege Write Protection Register \#5
  [n-128] GPIO{n}ReadPrivilegeWrProt (n=128..159) — GPIO{n} Read Privilege Write Protection
0xE24 GPIOE24 — Read Privilege Write Protection Register \#6
  [n-160] GPIO{n}ReadPrivilegeWrProt (n=160..191) — GPIO{n} Read Privilege Write Protection
0xE28 GPIOE28 — Read Privilege Write Protection Register \#7
  [1] GPIO193ReadPrivilegeWrProt — GPIO193 Read Privilege Write Protection
  [0] GPIO192ReadPrivilegeWrProt — GPIO192 Read Privilege Write Protection
